# psc3_p8_ppca register map
Vendor: Infineon Technologies; Series: PSC3_P8; File version: 1.0
CPU: CM33 r0p1, little endian, MPU, FPU, DSP, VTOR, 3 interrupt priority bits, 143 interrupts
Registers are 32-bit, read-write, reset 0x0 unless marked. A register's access mark holds for its fields unless they carry their own. Offsets are from the block's base; [hi:lo] are bit positions; lines under a group give offsets from that group; {n}, {i} and the like mark numbered series; 'fields as' and 'values as' point back to an identical list.

## PPCA_TCPWM0 (part 2 of 2) — S40 Timer/Counter/PWM
Base 0x43100000
Same registers: PPCA_TCPWM1 0x43200000, PPCA_TCPWM2 0x43300000, PPCA_TCPWM3 0x43400000
0x80000 TR_ALL_GF group — Glitch filter module for group trigger
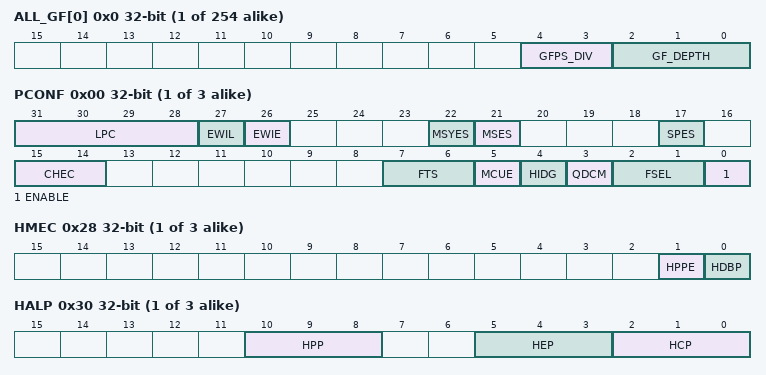
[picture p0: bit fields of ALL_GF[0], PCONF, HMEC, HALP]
  {0x0+4j} ALL_GF[{j}] (j=0..253) — Glitch filter register for All Group Triggers
    [4:3] GFPS_DIV — Select the glitch filter pre-scaling of the selected counter clock
      0=GFPS_DIVBY1 (Glitch filter pre-scaling of the selected counter clock. Divide by 1); 1=GFPS_DIVBY2 (Glitch filter pre-scaling of the selected counter clock. Divide by 2); 2=GFPS_DIVBY4 (Glitch filter pre-scaling of the selected counter clock. Divide by 4); 3=GFPS_DIVBY8 (Glitch filter pre-scaling of the selected counter clock. Divide by 8)
    [2:0] GF_DEPTH — Select the glitch filter depth
      0=DEPTHX0 (Glitch filter is turned off); 1=DEPTHX1 (Glitch filter depth is set to 1 x GFPS_DIVBYx of prescalar, where x is 1, 2, 4, 8); 2=DEPTHX2 (Glitch filter depth is set to 2 x GFPS_DIVBYx of prescalar, where x is 1, 2, 4, 8); 3=DEPTHX4 (Glitch filter depth is set to 4 x GFPS_DIVBYx of prescalar, where x is 1, 2, 4, 8); 4=DEPTHX8 (Glitch filter depth is set to 8 x GFPS_DIVBYx of prescalar, where x is 1, 2, 4, 8); 5=DEPTHX16 (Glitch filter depth is set to 16 x GFPS_DIVBYx of prescalar, where x is 1, 2, 4, 8); 6=DEPTHX32 (Glitch filter depth is set to 32 x GFPS_DIVBYx of prescalar, where x is 1, 2, 4, 8); 7=DEPTHX64 (Glitch filter depth is set to 64 x GFPS_DIVBYx of prescalar, where x is 1, 2, 4, 8)
0x90000 TR_ALL_SYNC_BYPASS group — Glitch filter module for group trigger
  {0x0+4j} TR_ALL_SYNC_BYPASS[{j}] (j=0..7) — Trigger Sync bypass for group trigger
    [31:0] SYNC_BYPASS — When set='1', bypass the sync stage for the corresponding group trigger
{0xA0000+0x4000*i} MOTIF_GRP[{i}] (i=0..2) group — Trigger Sync bypass for group trigger
  0x00 MOTIF group — MOTIF Module
    0x00 PCONF — Global control register
      [31:28] LPC — Low Pass Filters Configuration
        0=LP_DISABLE (Low pass filter disabled); 1=LP1 (Low pass of 1 clock cycle); 2=LP2 (Low pass of 2 clock cycle); 3=LP4 (Low pass of 4 clock cycle); 4=LP8 (Low pass of 8 clock cycle); 5=LP16 (Low pass of 16 clock cycle); 6=LP32 (Low pass of 32 clock cycle); 7=LP64 (Low pass of 64 clock cycle); 8=LP128 (Low pass of 128 clock cycle); 9=LP256 (Low pass of 256 clock cycle); 10=LP512 (Low pass of 512 clock cycle); 11=LP1024 (Low pass of 1024 clock cycle); {v}=RSVD{v} (N/A) (v=12..15)
      [27] EWIL — External Wrong Hall Event active level 0 - MOTIFx.EWHE signal is active HIGH 1 - MOTIFx.EWHE signal is active LOW
      [26] EWIE — External Wrong Hall Event enable 0 - External wrong hall event emulation signal, MOTIFx.EWHE, is disabled 1 - External wrong hall event emulation signal, MOTIFx.EWHE, is enabled.
      [22] MSYES — Multi-Channel pattern update msync trigger edge 0 - The signal used to enable a msync pattern update is active on the rising edge 1 - The signal used to enable a msync pattern update is active on the falling edge
      [21] MSES — Multi-Channel pattern update mset trigger edge 0 - The signal used to enable a mset pattern update is active on the rising edge 1 - The signal used to enable a mset pattern update is active on the falling edge
      [17] SPES — Edge selector for the sampling trigger This field selects which edge is used of the selected MOTIFx.HSD signal to trigger a sample of the Hall inputs. 0 - Rising edge 1 - Falling edge
      [15:14] CHEC — Correct Hall Event Clear selection
        0=WHE_OR_MP (OR between wrong hall event and module pin (MOTIFx.EWHE)); 1=WHE (Wrong Hall Event); 2=MODPIN (Module Pin - MOTIFx.EWHE); 3=RSVD3 (N/A)
      [7:6] FTS — Fault Hall event Selection
        values as CHEC
      [5] MCUE — Multi-Channel Pattern SW update enable 0 - Multi-Channel pattern update is controlled via HW 1 - Multi-Channel pattern update is controlled via SW
      [4] HIDG — Idle generation enable Setting this field to 1 disables the generation of the IDLE signal that forces a clear on the Multi-Channel pattern and run bit.
      [3] QDCM — Position Decoder Mode selection This field selects if the Position Decoder block is in Quadrature Mode or Direction Count Mode. In Quadrature mode, the position encoder is providing the phase signals, while in Direction Count Mode is providing a clock and a direction signal. 0 - Position encoder is in Quadrature Mode 1 - Position encoder is in Direction Count Mode.
      [2:1] FSEL — Function Selector
        0=HALLEN (Hall Sensor Mode enabled); 1=QUADEN (Quadrature Decoder Mode enabled); 2=STANDM (stand-alone Multi-Channel Mode enabled); 3=QDSTAN (Quadrature Decoder and stand-alone Multi_x0002_Channel Mode enabled)
      [0] ENABLE — MOTIF enable 0 - MOTIF disabled. 1 - MOTIF enabled. Enable MOTIF shall have the following effect: MOTIF clock is enabled,MOTIF registers are out of reset. Disable MOTIF shall have the following effect:MOTIF clock is gated, MOTIF non-retention registers get reset to default value, MOTIF retention register do not get reset, Output events get reset to default value, Interrupt output get reset to default value Modulation output get reset to default value.
    0x04 PSUS — Suspend Configuration
      [2:0] SUS — MOTIF Mode Suspend Config This field controls the entering in suspend for the MOTIF module.
        0=REQ_IGN (Suspend request ignored); 1=STOP (Stop immediately); 2=SUS_IDX (In quad mode and quad with stand-alone mode, suspend in the next index occurrence (QDCM =0). In any other mode. Stop immediately. When QDCM =1, it is considered as in other mode.); 3=SUS_PHA (In quad mode and quad with stand-alone mode (QDCM =0), suspend in the next phase (PhaseA or PhaseB) In any other mode. Stop immediately. When QDCM =1, it is considered as in other mode.); 4=STOP_RST (Stop immediately. Multi-Channel pattern is set to the reset value.); 5=SUS_SYN (Suspend with the synchronization of the PWM signal. Multi-Channel pattern is set to the reset value at the same time of the synchronization. In quad mode, stop immediately.); 6=RSVD1 (N/A); 7=RSVD2 (N/A)
    0x08 PRUNS — MOTIF run bit set
      [0] SRB — Set Run bit 0- Stop MOTIF. Writing an 0 into this bit stop the MOTIF and bring the state machine back to idle. 1- Start MOTIF. Writing an 1 into this bit sets the run bit of the module.A rising edge triggers the start machine. When a Fault event is detected, the Hardware can clear this bit to '0' and stop MOTIF as saftey mechanisim. The SW needs to re-configure MOTIF and start again MOTIF later. if LUT mode is enabled, LUTEN=1. The hardware can clear this bit to '0' and stop MOTIF as saftey mechanism when previous pattern is detected or when pattern mismatch is detetcted.
    0x10 PRUN ro — MOTIF run bit status
      [0] RB — Run Bit This field indicates if the module is in running or IDLE state. 0 - IDLE 1 - Running
    0x24 HIST wo — Hall Inputs Sample Trigger
      [0] HIS — Hall Inputs Sample Writting this bitfield with 1, will trigger a sample of the current hall inputs into the PDBG.HSP field. The hardware will automatically clear the HIS to 0. The sample of the hall inputs can be done even when the run bit of the module is not set. Requesting a sample when the module is running/normal operation, may incurr in wrong behavior. Read always returns 0.
    0x28 HMEC — Hall Mode Extra Config
      [1] HPPE — Previous Pattern Compare Enable Setting this bitfield to 1, enables the compare logic between the sampled hall input values and the previous hall pattern - HALP.HPP. This will be used together with the comparison of the current and expected pattern to generate a wrong hall event. 0 - Comparison between previous pattern and sampled pattern not used to generate a wrong hall event. 1 - Comparison between previous pattern and sampled pattern used to generate a wrong hall event.
      [0] HDBP — Hall Sensor Debounce Stage Bypass Setting this bitfield to 1, will disable the usage of the debounce delay pins, MOTIFx.HSD. This means that after the low pass filter, the hall inputs are immediately sampled and compared against the expected and current patterns. 0 - The hall inputs are only sampled after a valid transition at the MOTIFx.HSD pin. 1 - The hall inputs are sampled after the filtering stage and the MOTIFx.HSD pin usage is disabled.
    0x30 HALP ro — Hall Current and Expected patterns
      [10:8] HPP — Hall Previous Pattern if LUTEN = 0, this field contains the Hall Previous pattern. This field is updated with the HALPS.HPPS values every time that a correct hall event occurs. if LUTEN = 1, this field contains the Hall Previous pattern. This field is updated with the Hall LUT value every time that a correct hall event occurs.
      [5:3] HEP — Hall Expected Pattern if LUTEN = 0, this field contains the Hall Expected pattern. This field is updated with the HALPS.HEPS values every time that a correct hall event occurs. if LUTEN = 1, this field contains the Hall Expected pattern. This field is updated with the Hall LUT value every time that a correct hall event occurs.
      [2:0] HCP — Hall Current Pattern if LUTEN = 0, this field contains the Hall Current pattern. This field is updated with the HALPS.HCPS value every time that a correct hall event occurs. if LUTEN = 1, this field contains the Hall Current pattern. This field is updated with the Hall LUT value every time that a correct hall event occurs.
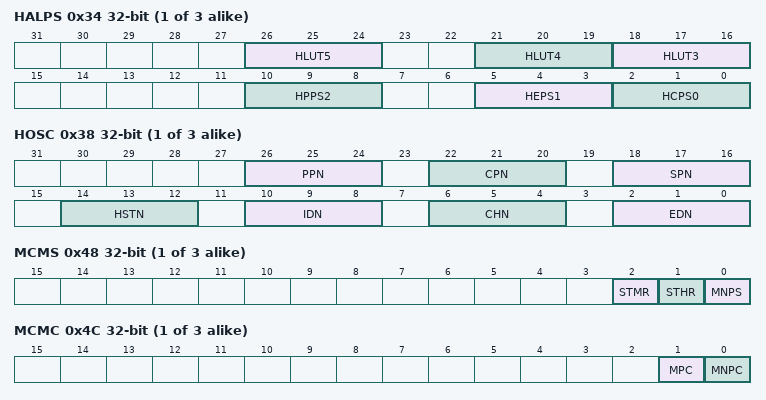
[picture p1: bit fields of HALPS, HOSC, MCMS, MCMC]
    0x34 HALPS — Hall Current and Expected shadow patterns
      [26:24] HLUT5 — Hall LUT data position 5 if LUTEN = 0 bitfield not used if LUTEN = 1 bitfield works as LUT position 5
      [21:19] HLUT4 — Hall LUT data position 4 if LUTEN = 0 bitfield not used if LUTEN = 1 bitfield works as LUT position 4
      [18:16] HLUT3 — Hall LUT data position 3 if LUTEN = 0 bitfield not used if LUTEN = 1 bitfield works as LUT position 3
      [10:8] HPPS2 — Shadow Hall Previous Pattern - HLUT2 if LUTEN = 0, this field contains the next Hall Previous pattern. This field is set on the HALP.HPP field every time that a correct hall event occurs. HPPS[0] - Hall Input 1 HPPS[1] - Hall Input 2 HPPS[2] - Hall Input 3 if LUTEN = 1 bitfield works as LUT position 2
      [5:3] HEPS1 — Shadow Hall expected Pattern - HLUT1 if LUTEN = 0, this field contains the next Hall Expected pattern. This field is set on the HALP.HEP field every time that a correct hall event occurs. HEPS[0] - Hall Input 1 HEPS[1] - Hall Input 2 HEPS[2] - Hall Input 3 if LUTEN = 1 bitfield works as LUT position 1
      [2:0] HCPS0 — Shadow Hall Current Pattern - HLUT0 if LUTEN = 0, this field contains the next Hall Current pattern value. This field is set on the HALP.HCP field every time that a correct hall event occurs. HCPS[0] - Hall Input 1 HCPS[1] - Hall Input 2 HCPS[2] - Hall Input 3 if HLUTEN = 1 bitfield works as LUT position 0
    0x38 HOSC — Hall Sensor Output Config
      [26:24] PPN — Previous Pattern Match Event Output Node This field selects to which output the event signalizing that the Hall Sensor inputs match the previous pattern is forward. Same coding description as the EDN field.
      [22:20] CPN — Current Pattern Match Event Output Node This field selects to which output the event signalizing that the Hall Sensor inputs match the current pattern is forward. Same coding description as the EDN field.
      [18:16] SPN — Stop Counters/Pattern Mismatch Event Output Node This field selects to which output the event signalizing that the Hall Sensor inputs do not match the current, the expected or the previous pattern is forward. Same coding description as the EDN field.
      [14:12] HSTN — Start Event Output Node This field selects to which output the event signalizing that the run bit was set is forward. Same coding description as the EDN field.
      [10:8] IDN — Idle/Wrong Hall Event Output Node This field selects to which output the OR event between the external fault pins, MOTIFx.EWHE, and the Wrong Hall Event is forward. Same coding description as the EDN field.
      [6:4] CHN — Correct Hall Event Output Node This field selects to which output the event signalizing that a correct hall event has been detected is forward. Same coding description as the EDN field.
      [2:0] EDN — Edge Detection Event Output Node This field selects to which output the event signalizing that an modification on the Hall Inputs is forward.
        0=NO_FWD (Signal is not forward to any output); {v}=FWD{v-1} (Forward to MOTIFx.OUT{v-1}) (v=1..7)
    0x40 MCM ro reset 0xAAAAAAAA — Multi-Channel Mode Pattern
      [31:0] MCMP — Multi-Channel Pattern This field contains the Multi-Channel Pattern that is going to be applied to the Multi-Channel outputs, MOTIFx.MOUT[31:0]. if MLUTEN=0, this field is updated with the value of the MCSM.MCMPS every time that a Multi-Channel pattern update is triggered. if MLUTEN=1, this bitfield is updated with the value select in MLUT0,1,2,3,4,5. These values get transferred to MOTIFx.MOUT[31:0]
    0x44 MCSM — Multi-Channel Mode shadow Pattern LUT0
      [31:0] MCMPS — Shadow Multi-Channel Pattern if MLUTEN=0, This field contains the next Multi-Channel Pattern. Every time that a Multi-Channel pattern transfer is triggered, this value is passed into the field MCM.MCMP. if MLUTEN=1, This field contains the Multi-Channel Pattern stored in Look-up table position 0. If Multi-Channel pattern transfer is triggered and MLUT0 is selected, this value is passed into field MCM.MCMP[31:0]
    0x48 MCMS wo — Multi-Channel Mode Control set
      [2] STMR — Multi-Channel Shadow Transfer Request Writing a 1 into this field leads to an immediate update of the field MCM.MCMP. A read always returns 0.
      [1] STHR — Hall Pattern Shadow Transfer Request Writing a 1 into this field leads to an immediate update of the fields HALP.HCP, HALP.HEP and HALP.HPP. A read always returns 0.
      [0] MNPS — Multi-Channel Pattern Update Enable Set Writing a 1 into this field enables the Multi-Channel pattern update (sets the MCMF.MSS bit). The update is not done immediately due to the fact that the trigger that synchronizes the update with the PWM is still needed. A read always returns 0.
    0x4C MCMC wo — Multi-Channel Mode Control clear
      [1] MPC — Multi-Channel Pattern clear Writing a 1 into this field clears the Multi-Channel Pattern value with the content of the MCPF register. A read always returns 0.
      [0] MNPC — Multi-Channel Pattern Update Enable Clear Writing a 1 into this field clears the MCMF.MSS bit. A read always returns 0.
    0x50 MCMF ro — Multi-Channel Mode flag status
      [0] MSS — Multi-Channel Pattern update status This field indicates if the Multi-Channel pattern is ready to be updated or not. When this field is set, the Multi-Channel pattern is updated when the triggering signal, selected from the MOTIFx.MSYNC, becomes active. 0 - Update of the Multi-Channel pattern is set 1 - Update of the Multi-Channel pattern is not set
    0x54 MCPF — Multi-Channel Pattern Fault
      [31:0] MCFV — Multi-Channel Fault Value This register contains the value that is going to be loaded into the Multi-Channel patter, MCP register, and fed consequently to the outputs, MOTIFx.MOUT[31:0]. This value is loaded into the MCP register whenever a fault is detected (via a wrong hall event or one of the MOTIFx.EWHEy pins) or whenever the software requests a pattern clear via the MCMC.MPC bitfield.
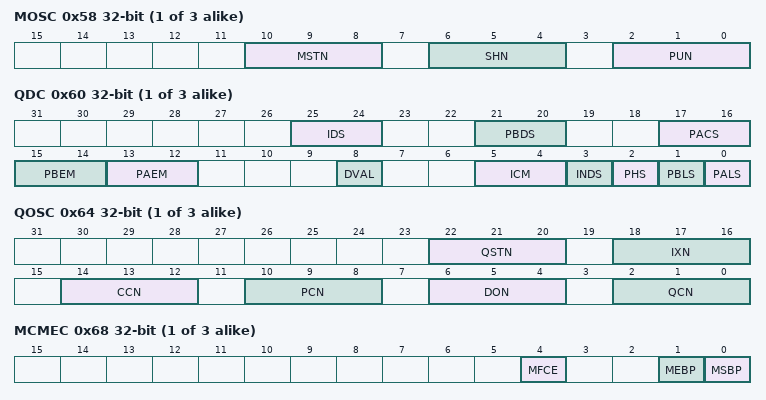
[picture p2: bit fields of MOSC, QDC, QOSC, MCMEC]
    0x58 MOSC — Multi-Channel Output Config
      [10:8] MSTN — Start Event Output Node This field selects to which output the event signalizing that the run bit was set is forward. Same coding description as the PUN field.
      [6:4] SHN — Update Sync Event Output Node This field selects to which output, the event that is used to synchronize the Multi-Channel Pattern update has happened after MSYNC edge detected, is forward. Same coding description as the PUN field.
      [2:0] PUN — Pattern Update Event Output Node This field selects to which output, the event signalizing that a Multi-Channel pattern update is enabled (MSS is set), is forward.
        values as MOTIF_GRP[0].MOTIF.HOSC.EDN
    0x60 QDC — Quadrature Decoder Configuration
      [25:24] IDS — Index Selector Selects which signal is used as Index signal if in Quadrature Decoder Mode:
        0=DISABLE (Disabled); 1=POSI0; 2=POSI1; 3=POSI2
      [21:20] PBDS — Phase B or Direction Selector Selects which signal is used as Phase B signal if in Quadrature Decoder Mode or as Direction if in Direction Count Mode:
        0=DISABLE (Disabled); 1=POSI0; 2=POSI1; 3=POSI2
      [17:16] PACS — Phase A or Clock Selector Selects which signal is used as Phase A signal if in Quadrature Decoder Mode or as Clock if in Direction Count Mode:
        0=DISABLE (Disabled); 1=POSI0; 2=POSI1; 3=POSI2
      [15:14] PBEM — Phase B Edge Mode Note: Selecting BOTH in one PHASE, implies that other PHASE should not be RISE/FALL. Selecting NONE in one PHASE, implies that other PHASE should not be NONE. Invalid combination can lead to unexpected behavior
        0=BOTH (clock is decoded on rising and falling edges of the Phase B signal); 1=RISE (clock is decoded on rising edge of the Phase B signal); 2=FALL (clock is decoded on falling edge of the Phase B signal); 3=NONE (Clock is not decoded for PHASE B)
      [13:12] PAEM — Phase A Edge Mode Note: Selecting BOTH in one PHASE, implies that other PHASE should not be RISE/FALL. Selecting NONE in one PHASE, implies that other PHASE should not be NONE. Invalid combination can lead to unexpected behavior
        0=BOTH (clock is decoded on rising and falling edges of the Phase A signal); 1=RISE (clock is decoded on rising edge of the Phase A signal); 2=FALL (clock is decoded on falling edge of the Phase A signal); 3=NONE (Clock is not decoded for PHASE A)
      [8] DVAL ro — Current rotation direction 0 - Counterclockwise rotation 1 - Clockwise rotation
      [5:4] ICM — Index Marker generations control This field controls the generation of the index marker that is linked PRGINDX event.
        0=NO_IDX (No index marker generation); 1=1ST_IDX (Only first index occurrence generated); 2=ALL_IDX (All index occurrences generated); 3=RSVD3 (N/A)
      [3] INDS — Index Signal Level selector 0 - Index signal is active HIGH 1 - Index signal is active LOW
      [2] PHS — Phase signals swap 0 - Phase A is the leading signal for clockwise rotation 1 - Phase B is the leading signal for clockwise rotation
      [1] PBLS — Phase B Level selector 0 - Phase B is active HIGH 1 - Phase B is active LOW
      [0] PALS — Phase A Level selector 0 - Phase A is active HIGH 1 - Phase A is active LOW
    0x64 QOSC — Quadrature Output Config
      [22:20] QSTN — Start Event Output Node This field selects to which output the event signalizing that the run bit was set is forward. Same coding description as the QCN field.
      [18:16] IXN — Index Event Output Node This field selects to which output the event signalizing that an index/zero marker was detected, is forward. This event is only generated when the index input has been detected and the rotation direction did not change (between two index occurrences). internal indx Same coding description as the QCN field.
      [14:12] CCN — Clear/Capture Event Output Node This field selects to which output the event signalizing that an index/zero marker was detected, is forward. This can be used as a capture or clear function for a timer, to measure time between index events. internal prgindx Same coding description as the QCN field.
      [10:8] PCN — Period Clock Event Output Node This field selects to which output, the period clock (PCLK) event, is forward. Same coding description as the QCN field.
      [6:4] DON — Direction Event Output Node This field selects to which output, the direction signal (QDIR), is forward. Same coding description as the QCN field.
      [2:0] QCN — Quadrature Clock Event Output Node This field selects to which output, the quadrature clock (QCLK) event, is forward.
        values as MOTIF_GRP[0].MOTIF.HOSC.EDN
    0x68 MCMEC — Multi-Channel Extra Config
      [4] MFCE — Multi-Channel Fault Clear Enable Setting this bitfield to 1 will enable a clear of the Multi-Channel pattern, whenever a Hall Fault Event is detected. The Multi-Channel pattern will be cleared with the value programmed in the MCFV field. 0 - Multi-Channel pattern clear with Hall Fault Event disabled. 1 - Multi-Channel pattern clear with Hall Fault Event enabled.
      [1] MEBP — Multi-Channel Pattern Enable Delay Bypass Setting this bitfield to 1 will bypass the delay between a Correct Hall Event and the enable of the Multi-Channel Patter update. 0 - Enable of the Multi-Channel Pattern update is only done after the external SET signal is detected - MOTIFx.MSET. 1 - Enable of the Multi-Channel Pattern update is done immediately after a Correct Hall Event is detected - only valid when PCONF.MCUE is 0.
      [0] MSBP — Multi-Channel Mode Sync Bypass Setting this bitfield to 1 will dictate that whenever the MCMF.MSS bitfield is 1, a pattern update will occur immediately (without waiting for the sync signal - MOTIFx.MSYNC). 0 - Update of the Multi-Channel pattern is only done after the sync signal is detected - MOTIFx.MSYNC. 1 - Update of the Multi-Channel pattern is done immediately after the MCMF.MSS field is set.
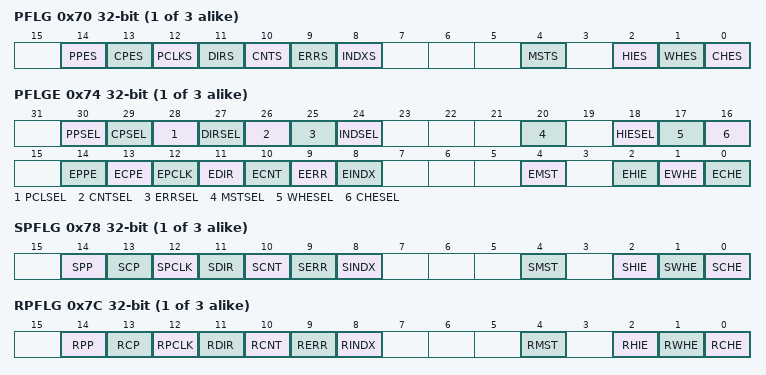
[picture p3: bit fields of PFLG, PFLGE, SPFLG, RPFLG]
    0x70 PFLG ro — MOTIF interrupt status
      [14] PPES — Previous Pattern Match Status 0 - Equality between Sampled Hall input values and Previous Pattern value not detected. 1 - Equality between Sampled Hall input values and Previous Pattern value detected.
      [13] CPES — Current Pattern Match Status 0 - Equality between Sampled Hall input values and Current Pattern value not detected. 1 - Equality between Sampled Hall input values and Current Pattern value detected.
      [12] PCLKS — Quadrature Period Clk Status 0 - Period clock not generated 1 - Period clock generated
      [11] DIRS — Quadrature Direction Change 0 - Change on direction not detected 1 - Change on direction detected
      [10] CNTS — Quadrature CLK Status 0 - Quadrature clock not generated 1 - Quadrature clock generated
      [9] ERRS — Quadrature Phase Error Status 0 - Phase Error event not detected 1 - Phase Error event detected
      [8] INDXS — Quadrature Index Status 0 - Index event not detected 1 - Index event detected
      [4] MSTS — Multi-Channel pattern shadow transfer status 0 - Shadow transfer not done 1 - Shadow transfer done
      [2] HIES — Hall Inputs Update Status 0 - Transition on the Hall Inputs not detected 1 - Transition on the Hall Inputs detected
      [1] WHES — Wrong Hall Event Status 0 - Wrong Hall Event not detected 1 - Wrong Hall Event detected
      [0] CHES — Correct Hall Event Status 0 - Correct Hall Event not detected 1 - Correct Hall Event detected
    0x74 PFLGE — MOTIF interrupt enable
      [30] PPSEL — Previous Pattern Match Event Service Request Selector 0 - Previous Pattern Match Event interrupt forward to MOTIFx.SR0 1 - Previous Pattern Match Event interrupt forward to MOTIFx.SR1
      [29] CPSEL — Current Pattern Match Event Service Request Selector 0 - Current Pattern Match Event interrupt forward to MOTIFx.SR0 1 - Current Pattern Match Event interrupt forward to MOTIFx.SR1
      [28] PCLSEL — Quadrature Period clock Event Service Request Selector 0 - Quadrature Period clock Event interrupt forward to MOTIFx.SR0 1 - Quadrature Period clock Event interrupt forward to MOTIFx.SR1
      [27] DIRSEL — Quadrature Direction Update Event Service Request Selector 0 - Quadrature Direction Update Event interrupt forward to MOTIFx.SR0 1 - Quadrature Direction Update Event interrupt forward to MOTIFx.SR1
      [26] CNTSEL — Quadrature Clock Event Service Request Selector 0 - Quadrature Clock Event interrupt forward to MOTIFx.SR0 1 - Quadrature Clock Event interrupt forward to MOTIFx.SR1
      [25] ERRSEL — Quadrature Phase Error Event Service Request Selector 0 - Quadrature Phase error Event interrupt forward to MOTIFx.SR0 1 - Quadrature Phase error Event interrupt forward to MOTIFx.SR1
      [24] INDSEL — Quadrature Index Event Service Request Selector 0 - Quadrature Index Event interrupt forward to MOTIFx.SR0 1 - Quadrature Index Event interrupt forward to MOTIFx.SR1
      [20] MSTSEL — Multi-Channel pattern Update Event Service Request Selector 0 - Multi-Channel pattern Update Event interrupt forward to MOTIFx.SR0 1 - Multi-Channel pattern Update Event interrupt forward to MOTIFx.SR1
      [18] HIESEL — Hall Inputs Update Event Service Request Selector 0 - Hall Inputs Update Event interrupt forward to MOTIFx.SR0 1 - Hall Inputs Update Event interrupt forward to MOTIFx.SR1
      [17] WHESEL — Wrong Hall Event Service Request Selector 0 - Wrong Hall Event interrupt forward to MOTIFx.SR0 1 - Wrong Hall Event interrupt forward to MOTIFx.SR1
      [16] CHESEL — Correct Hall Event Service Request Selector 0 - Correct Hall Event interrupt forward to MOTIFx.SR0 1 - Correct Hall Event interrupt forward to MOTIFx.SR1
      [14] EPPE — Previous Pattern Match interrupt Enable 0 - Previous Pattern Match event interrupt disabled 1 - Previous Pattern Match event interrupt enabled
      [13] ECPE — Current Pattern Match interrupt Enable 0 - Current Pattern Match event interrupt disabled 1 - Current Pattern Match event interrupt enabled
      [12] EPCLK — Quadrature Period CLK interrupt Enable 0 - Quadrature Period CLK event interrupt disabled 1 - Quadrature Period CLK event interrupt enabled
      [11] EDIR — Quadrature direction change interrupt Enable 0 - Direction change event interrupt disabled 1 - Direction change event interrupt enabled
      [10] ECNT — Quadrature CLK interrupt Enable 0 - Quadrature CLK event interrupt disabled 1 - Quadrature CLK event interrupt enabled
      [9] EERR — Quadrature Phase Error Enable 0 - Phase error event interrupt disabled 1 - Phase error event interrupt enabled
      [8] EINDX — Quadrature Index Event Enable 0 - Index event interrupt disabled 1 - Index event interrupt enabled
      [4] EMST — Multi-Channel pattern shadow transfer enable 0 - Shadow transfer event interrupt disabled 1 - Shadow transfer event interrupt enabled
      [2] EHIE — Hall Input Update Enable 0 - Update of the Hall Inputs interrupt is disabled 1 - Update of the Hall Inputs interrupt is enabled
      [1] EWHE — Wrong Hall Event Enable 0 - Wrong Hall Event interrupt disabled 1 - Wrong Hall Event interrupt enabled
      [0] ECHE — Correct Hall Event Enable 0 - Correct Hall Event interrupt disabled 1 - Correct Hall Event interrupt enabled
    0x78 SPFLG wo — Interrupt set register
      [14] SPP — Previous Pattern Match flag set Writing a 1B to this field sets the PFLG.PPES bit field. An interrupt pulse is generated. A read always returns 0.
      [13] SCP — Current Pattern Match flag set Writing a 1 to this field sets the PFLG.CPES bit field. An interrupt pulse is generated. A read always returns 0.
      [12] SPCLK — Quadrature period clock flag set Writing a 1 to this field sets the PFLG.PCLKS bit field. An interrupt pulse is generated. A read always returns 0.
      [11] SDIR — Quadrature Direction flag set Writing a 1 to this field sets the PFLG.DIRS bit field. An interrupt pulse is generated. A read always returns 0.
      [10] SCNT — Quadrature CLK flag set Writing a 1 to this field sets the PFLG.CNTS bit field. An interrupt pulse is generated. A read always returns 0.
      [9] SERR — Quadrature Phase Error flag set Writing a 1 to this field sets the PFLG.ERRS bit field. An interrupt pulse is generated. A read always returns 0.
      [8] SINDX — Quadrature Index flag set Writing a 1 to this field sets the PFLG.INDXS bit field. An interrupt pulse is generated. A read always returns 0.
      [4] SMST — Multi-Channel Pattern shadow transfer flag set Writing a 1 to this field sets the PFLG.MSTS bit field. An interrupt pulse is generated. A read always returns 0.
      [2] SHIE — Hall Inputs Update Event flag set Writing a 1 to this field sets the PFLG.HIES bit field. An interrupt pulse is generated. A read always returns 0.
      [1] SWHE — Wrong Hall Event flag set Writing a 1 to this field sets the PFLG.WHES bit field. An interrupt pulse is generated. A read always returns 0.
      [0] SCHE — Correct Hall Event flag set Writing a 1 to this field sets the PFLG.CHES bit field. An interrupt pulse is generated. A read always returns 0.
    0x7C RPFLG wo — Interrupt clear register
      [14] RPP — Previous Pattern Match flag clear Writing a 1 to this field clears the PFLG.PPES bit field. A read always returns 0.
      [13] RCP — Current Pattern Match flag clear Writing a 1 to this field clears the PFLG.CPES bit field. A read always returns 0.
      [12] RPCLK — Quadrature period clock flag clear Writing a 1 to this field clears the PFLG.PCLKS bit field. A read always returns 0.
      [11] RDIR — Quadrature Direction flag clear Writing a 1 to this field clears the PFLG.DIRS bit field. A read always returns 0.
      [10] RCNT — Quadrature CLK flag clear Writing a 1 to this field clears the PFLG.CNTS bit field. A read always returns 0.
      [9] RERR — Quadrature Phase Error flag clear Writing a 1 to this field clears the PFLG.ERRS bit field. A read always returns 0.
      [8] RINDX — Quadrature Index flag clear Writing a 1 to this field clears the PFLG.INDXS bit field. A read always returns 0.
      [4] RMST — Multi-Channel Pattern shadow transfer flag clear Writing a 1 to this field clears the PFLG.MSTS bit field. A read always returns 0.
      [2] RHIE — Hall Inputs Update Event flag clear Writing a 1 to this field clears the PFLG.HIES bit field. A read always returns 0.
      [1] RWHE — Wrong Hall Event flag clear Writing a 1 to this field clears the PFLG.WHES bit field. A read always returns 0.
      [0] RCHE — Correct Hall Event flag clear Writing a 1 to this field clears the PFLG.CHES bit field. A read always returns 0.
    {0x7C+4k} MCSM{k} (k=1..5) — Multi-Channel Mode shadow pattern LUT{k}
      [31:0] MLUT{k} — Multi-Channel LUT {k} if MLUTEN=0 this bitfield is not used if MLUTEN=1 this field contains the Multi-Channel Pattern stored in Look-up table position {k}. If Multi-Channel pattern transfer is triggered and MLUT{k} is selected, this value is passed into the field MCM.MCMP[31:0]
    0x94 CLUT — Hall Mode LUT config
      [0] LUTEN — HALL LUT enable Setting this bitfield to 1, will enable the usage of the Hall Look-up table. 0 - Hall LUT disabled, HCPS, HEPS, HPPS are used. HLUT3, HLUT4,HLUT5 not used. 1 - Hall LUT enabled, HCPS, HEPS, HPPS, HLUT3, HLUT4,HLUT5 works as data container for the LUT. Every time that a correct hall event occurs the LUT provides new values to HALP register
    0x98 SLUT ro — Hall Mode LUT status
      [2:0] PTR — HALL LUT Pointer status This field contains the pointer address to HALL LUT current pattern. LUTEN must be set, if LUTEN is 0, this bitfield is always 0. Valid values are 0,1,2,3,4,5. Invalid values 6,7
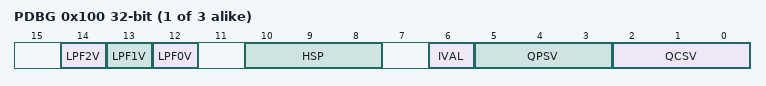
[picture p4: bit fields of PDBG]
    0x100 PDBG ro — MOTIF Debug Register
      [14] LPF2V — Low Pass filter 2 valid state 0 - Low pass filter has not output valid data 1 - Low pass filter has output valid data
      [13] LPF1V — Low Pass filter 1 valid state 0 - Low pass filter has not output valid data 1 - Low pass filter has output valid data
      [12] LPF0V — Low Pass filter 0 valid state 0 - Low pass filter has not output valid data 1 - Low pass filter has output valid data
      [10:8] HSP — Hall Current Sampled Pattern HSP[0] - Hall Input 1 HSP[1] - Hall Input 2 HSP[2] - Hall Input 3
      [6] IVAL — Current Index Value
      [5:3] QPSV — Quadrature Decoder Previous state This field stores the previous state of the quadrature decoder state machine. The ready indicates that the state machine has processed the first values present at the MOTIF inputs (this may not be immediate due to the propgation time of the low pass filters - if enabled). QPSV[0] - Phase B QPSV[1] - Phase A QPSV[2] - ready
      [2:0] QCSV — Quadrature Decoder Current state This field stores the current state of the quadrature decoder state machine. The ready indicates that the state machine has processed the first values present at the MOTIF inputs (this may not be immediate due to the propgation time of the low pass filters - if enabled). QCSV[0] - Phase B QCSV[1] - Phase A QCSV[2] - ready
    {0x104+4k} PLP{k}S ro (k=0..2) — MOTIF Low Pass {k} Status
      [9:0] LPP{k} — Actual count of the Low Pass Filter
